VERSION ""

NS_ :

BS_:

BU_:

BO_ 3221225472 VECTOR__INDEPENDENT_SIG_MSG: 0 Vector__XXX
 SG_ NewSignal_0001 : 0|8@1+ (1,0) [0|0] "" Vector__XXX

BO_ 128 Sync: 0 Vector__XXX

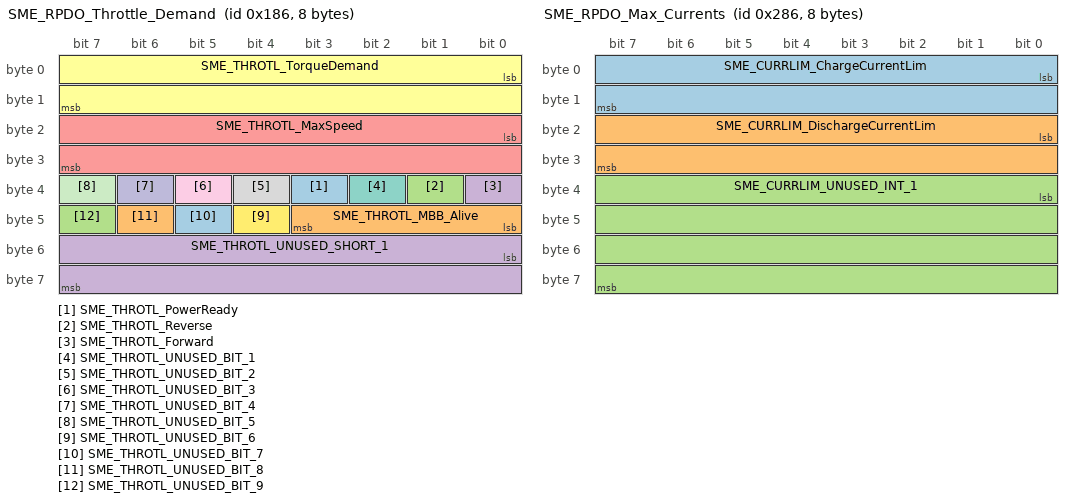
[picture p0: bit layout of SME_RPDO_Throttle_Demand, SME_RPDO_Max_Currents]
BO_ 390 SME_RPDO_Throttle_Demand: 8 Vector__XXX
 SG_ SME_THROTL_PowerReady : 35|1@1- (1,0) [0|1] "" Vector__XXX
 SG_ SME_THROTL_MBB_Alive : 40|4@1+ (1,0) [0|15] "" Vector__XXX
 SG_ SME_THROTL_Reverse : 33|1@1- (1,0) [0|1] "" Vector__XXX
 SG_ SME_THROTL_Forward : 32|1@1- (1,0) [0|1] "" Vector__XXX
 SG_ SME_THROTL_MaxSpeed : 16|16@1- (1,0) [-32768|32767] "RPM" Vector__XXX
 SG_ SME_THROTL_TorqueDemand : 0|16@1- (1,0) [-32767|32767] "Q15" Vector__XXX
 SG_ SME_THROTL_UNUSED_BIT_1 : 34|1@1+ (1,0) [0|0] "" Vector__XXX
 SG_ SME_THROTL_UNUSED_BIT_2 : 36|1@1+ (1,0) [0|0] "" Vector__XXX
 SG_ SME_THROTL_UNUSED_BIT_3 : 37|1@1+ (1,0) [0|0] "" Vector__XXX
 SG_ SME_THROTL_UNUSED_BIT_4 : 38|1@1+ (1,0) [0|0] "" Vector__XXX
 SG_ SME_THROTL_UNUSED_BIT_5 : 39|1@1+ (1,0) [0|0] "" Vector__XXX
 SG_ SME_THROTL_UNUSED_BIT_6 : 44|1@1+ (1,0) [0|0] "" Vector__XXX
 SG_ SME_THROTL_UNUSED_BIT_7 : 45|1@1+ (1,0) [0|0] "" Vector__XXX
 SG_ SME_THROTL_UNUSED_BIT_8 : 46|1@1+ (1,0) [0|0] "" Vector__XXX
 SG_ SME_THROTL_UNUSED_BIT_9 : 47|1@1+ (1,0) [0|0] "" Vector__XXX
 SG_ SME_THROTL_UNUSED_SHORT_1 : 48|16@1+ (1,0) [0|0] "" Vector__XXX

BO_ 646 SME_RPDO_Max_Currents: 8 Vector__XXX
 SG_ SME_CURRLIM_ChargeCurrentLim : 0|16@1+ (1,0) [0|65535] "A" Vector__XXX
 SG_ SME_CURRLIM_DischargeCurrentLim : 16|16@1+ (1,0) [0|65535] "A" Vector__XXX
 SG_ SME_CURRLIM_UNUSED_INT_1 : 32|32@1+ (1,0) [0|0] "" Vector__XXX

BO_ 1154 SME_TPDO_Torque_speed: 8 Vector__XXX
 SG_ SME_TRQSPD_SOC_Low_Traction : 32|1@1+ (1,0) [0|1] "" Vector__XXX
 SG_ SME_TRQSPD_SOC_Low_Hydraulic : 33|1@1+ (1,0) [0|1] "" Vector__XXX
 SG_ SME_TRQSPD_Reverse : 34|1@1+ (1,0) [0|1] "" Vector__XXX
 SG_ SME_TRQSPD_Forward : 35|1@1+ (1,0) [0|1] "" Vector__XXX
 SG_ SME_TRQSPD_Park_Brake : 36|1@1+ (1,0) [0|1] "" Vector__XXX
 SG_ SME_TRQSPD_Pedal_Brake : 37|1@1+ (1,0) [0|1] "" Vector__XXX
 SG_ SME_TRQSPD_Controller_Overtermp : 38|1@1+ (1,0) [0|1] "" Vector__XXX
 SG_ SME_TRQSPD_Key_switch_overvolt : 39|1@1+ (1,0) [0|1] "" Vector__XXX
 SG_ SME_TRQSPD_Key_switch_undervolt : 40|1@1+ (1,0) [0|1] "" Vector__XXX
 SG_ SME_TRQSPD_Running : 41|1@1+ (1,0) [0|1] "" Vector__XXX
 SG_ SME_TRQSPD_Traction : 42|1@1+ (1,0) [0|1] "" Vector__XXX
 SG_ SME_TRQSPD_Hydraulic : 43|1@1+ (1,0) [0|1] "" Vector__XXX
 SG_ SME_TRQSPD_Powering_Enabled : 44|1@1+ (1,0) [0|1] "" Vector__XXX
 SG_ SME_TRQSPD_Powering_Ready : 45|1@1+ (1,0) [0|1] "" Vector__XXX
 SG_ SME_TRQSPD_contactor_closed : 47|1@1+ (1,0) [0|1] "" Vector__XXX
 SG_ SME_TRQSPD_Precharging : 46|1@1+ (1,0) [0|1] "" Vector__XXX
 SG_ SME_TRQSPD_Speed : 0|16@1+ (1,0) [-32768|32767] "RPM" Vector__XXX
 SG_ SME_TRQSPD_MotorFlags : 48|16@1+ (1,0) [0|65535] "" Vector__XXX
 SG_ SME_TRQSPD_Torque : 16|16@1- (1,0) [-32767|32767] "Q15" Vector__XXX

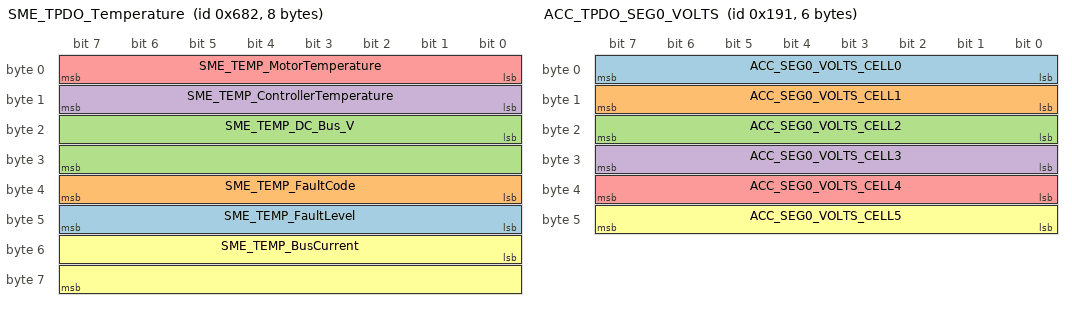
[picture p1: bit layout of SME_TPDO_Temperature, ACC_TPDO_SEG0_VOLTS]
BO_ 1666 SME_TPDO_Temperature: 8 Vector__XXX
 SG_ SME_TEMP_FaultLevel : 40|8@1+ (1,0) [0|255] "" Vector__XXX
 SG_ SME_TEMP_FaultCode : 32|8@1+ (1,0) [0|255] "" Vector__XXX
 SG_ SME_TEMP_DC_Bus_V : 16|16@1+ (0.1,0) [0|6553.5] "V" Vector__XXX
 SG_ SME_TEMP_ControllerTemperature : 8|8@1+ (1,-40) [0|255] "C" Vector__XXX
 SG_ SME_TEMP_MotorTemperature : 0|8@1+ (1,-40) [0|255] "C" Vector__XXX
 SG_ SME_TEMP_BusCurrent : 48|16@1- (0.1,0) [-3276.8|3276.7] "A" Vector__XXX

BO_ 400 ACC_TPDO_STATUS: 8 Vector__XXX

BO_ 656 ACC_TPDO_POWER: 8 Vector__XXX
 SG_ ACC_POWER_PACK_VOLTAGE : 0|16@1+ (0.01,0) [0|655.35] "V" Vector__XXX
 SG_ ACC_POWER_SOC : 16|8@1+ (1,0) [0|255] "Percentage" Vector__XXX

BO_ 401 ACC_TPDO_SEG0_VOLTS: 6 Vector__XXX
 SG_ ACC_SEG0_VOLTS_CELL0 : 0|8@1+ (0.01,2) [2|4.55] "V" Vector__XXX
 SG_ ACC_SEG0_VOLTS_CELL1 : 8|8@1+ (0.01,2) [2|4.55] "V" Vector__XXX
 SG_ ACC_SEG0_VOLTS_CELL2 : 16|8@1+ (0.01,2) [2|4.55] "V" Vector__XXX
 SG_ ACC_SEG0_VOLTS_CELL3 : 24|8@1+ (0.01,2) [2|4.55] "V" Vector__XXX
 SG_ ACC_SEG0_VOLTS_CELL4 : 32|8@1+ (0.01,2) [2|4.55] "V" Vector__XXX
 SG_ ACC_SEG0_VOLTS_CELL5 : 40|8@1+ (0.01,2) [2|4.55] "V" Vector__XXX

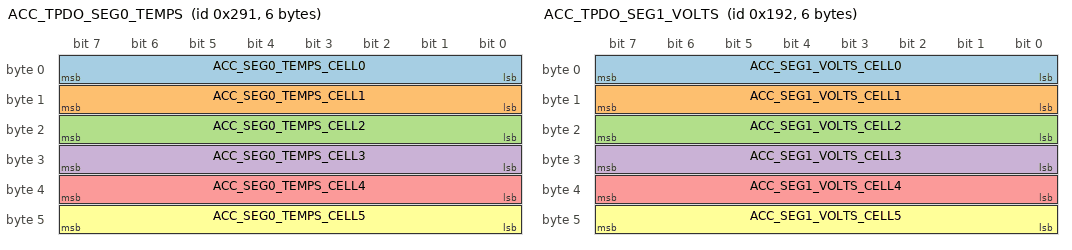
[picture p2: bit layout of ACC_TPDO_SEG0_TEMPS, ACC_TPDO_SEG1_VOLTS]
BO_ 657 ACC_TPDO_SEG0_TEMPS: 6 Vector__XXX
 SG_ ACC_SEG0_TEMPS_CELL0 : 0|8@1- (1,0) [-128|127] "C" Vector__XXX
 SG_ ACC_SEG0_TEMPS_CELL1 : 8|8@1- (1,0) [-128|127] "C" Vector__XXX
 SG_ ACC_SEG0_TEMPS_CELL2 : 16|8@1- (1,0) [-128|127] "C" Vector__XXX
 SG_ ACC_SEG0_TEMPS_CELL3 : 24|8@1- (1,0) [-128|127] "C" Vector__XXX
 SG_ ACC_SEG0_TEMPS_CELL4 : 32|8@1- (1,0) [-128|127] "C" Vector__XXX
 SG_ ACC_SEG0_TEMPS_CELL5 : 40|8@1- (1,0) [-128|127] "C" Vector__XXX

BO_ 402 ACC_TPDO_SEG1_VOLTS: 6 Vector__XXX
 SG_ ACC_SEG1_VOLTS_CELL0 : 0|8@1+ (0.01,2) [2|4.55] "V" Vector__XXX
 SG_ ACC_SEG1_VOLTS_CELL1 : 8|8@1+ (0.01,2) [2|4.55] "V" Vector__XXX
 SG_ ACC_SEG1_VOLTS_CELL2 : 16|8@1+ (0.01,2) [2|4.55] "V" Vector__XXX
 SG_ ACC_SEG1_VOLTS_CELL3 : 24|8@1+ (0.01,2) [2|4.55] "V" Vector__XXX
 SG_ ACC_SEG1_VOLTS_CELL4 : 32|8@1+ (0.01,2) [2|4.55] "V" Vector__XXX
 SG_ ACC_SEG1_VOLTS_CELL5 : 40|8@1+ (0.01,2) [2|4.55] "V" Vector__XXX

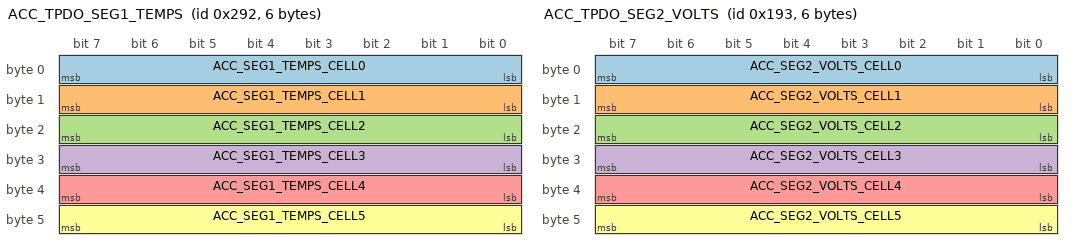
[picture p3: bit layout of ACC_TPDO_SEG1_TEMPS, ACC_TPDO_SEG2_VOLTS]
BO_ 658 ACC_TPDO_SEG1_TEMPS: 6 Vector__XXX
 SG_ ACC_SEG1_TEMPS_CELL0 : 0|8@1- (1,0) [-128|127] "C" Vector__XXX
 SG_ ACC_SEG1_TEMPS_CELL1 : 8|8@1- (1,0) [-128|127] "C" Vector__XXX
 SG_ ACC_SEG1_TEMPS_CELL2 : 16|8@1- (1,0) [-128|127] "C" Vector__XXX
 SG_ ACC_SEG1_TEMPS_CELL3 : 24|8@1- (1,0) [-128|127] "C" Vector__XXX
 SG_ ACC_SEG1_TEMPS_CELL4 : 32|8@1- (1,0) [-128|127] "C" Vector__XXX
 SG_ ACC_SEG1_TEMPS_CELL5 : 40|8@1- (1,0) [-128|127] "C" Vector__XXX

BO_ 403 ACC_TPDO_SEG2_VOLTS: 6 Vector__XXX
 SG_ ACC_SEG2_VOLTS_CELL0 : 0|8@1+ (0.01,2) [2|4.55] "V" Vector__XXX
 SG_ ACC_SEG2_VOLTS_CELL1 : 8|8@1+ (0.01,2) [2|4.55] "V" Vector__XXX
 SG_ ACC_SEG2_VOLTS_CELL2 : 16|8@1+ (0.01,2) [2|4.55] "V" Vector__XXX
 SG_ ACC_SEG2_VOLTS_CELL3 : 24|8@1+ (0.01,2) [2|4.55] "V" Vector__XXX
 SG_ ACC_SEG2_VOLTS_CELL4 : 32|8@1+ (0.01,2) [2|4.55] "V" Vector__XXX
 SG_ ACC_SEG2_VOLTS_CELL5 : 40|8@1+ (0.01,2) [2|4.55] "V" Vector__XXX

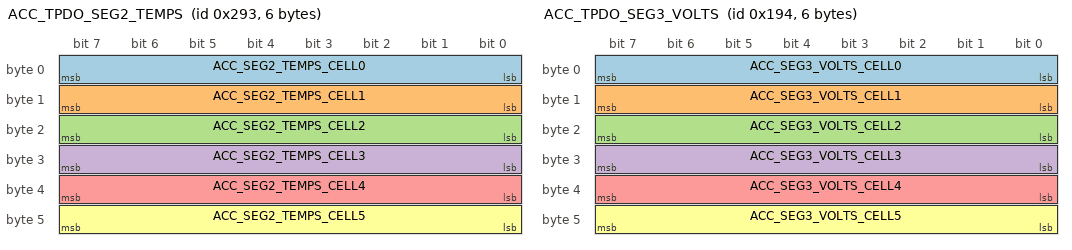
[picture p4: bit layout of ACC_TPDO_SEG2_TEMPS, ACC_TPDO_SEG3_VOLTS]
BO_ 659 ACC_TPDO_SEG2_TEMPS: 6 Vector__XXX
 SG_ ACC_SEG2_TEMPS_CELL0 : 0|8@1- (1,0) [-128|127] "C" Vector__XXX
 SG_ ACC_SEG2_TEMPS_CELL1 : 8|8@1- (1,0) [-128|127] "C" Vector__XXX
 SG_ ACC_SEG2_TEMPS_CELL2 : 16|8@1- (1,0) [-128|127] "C" Vector__XXX
 SG_ ACC_SEG2_TEMPS_CELL3 : 24|8@1- (1,0) [-128|127] "C" Vector__XXX
 SG_ ACC_SEG2_TEMPS_CELL4 : 32|8@1- (1,0) [-128|127] "C" Vector__XXX
 SG_ ACC_SEG2_TEMPS_CELL5 : 40|8@1- (1,0) [-128|127] "C" Vector__XXX

BO_ 404 ACC_TPDO_SEG3_VOLTS: 6 Vector__XXX
 SG_ ACC_SEG3_VOLTS_CELL0 : 0|8@1+ (0.01,2) [2|4.55] "V" Vector__XXX
 SG_ ACC_SEG3_VOLTS_CELL1 : 8|8@1+ (0.01,2) [2|4.55] "V" Vector__XXX
 SG_ ACC_SEG3_VOLTS_CELL2 : 16|8@1+ (0.01,2) [2|4.55] "V" Vector__XXX
 SG_ ACC_SEG3_VOLTS_CELL3 : 24|8@1+ (0.01,2) [2|4.55] "V" Vector__XXX
 SG_ ACC_SEG3_VOLTS_CELL4 : 32|8@1+ (0.01,2) [2|4.55] "V" Vector__XXX
 SG_ ACC_SEG3_VOLTS_CELL5 : 40|8@1+ (0.01,2) [2|4.55] "V" Vector__XXX

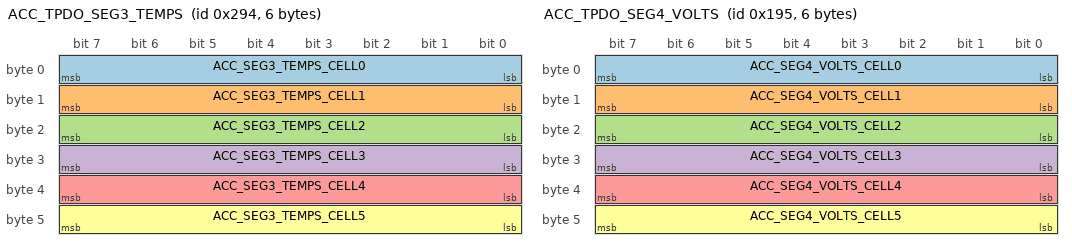
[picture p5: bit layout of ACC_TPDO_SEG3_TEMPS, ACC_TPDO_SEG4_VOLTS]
BO_ 660 ACC_TPDO_SEG3_TEMPS: 6 Vector__XXX
 SG_ ACC_SEG3_TEMPS_CELL0 : 0|8@1- (1,0) [-128|127] "C" Vector__XXX
 SG_ ACC_SEG3_TEMPS_CELL1 : 8|8@1- (1,0) [-128|127] "C" Vector__XXX
 SG_ ACC_SEG3_TEMPS_CELL2 : 16|8@1- (1,0) [-128|127] "C" Vector__XXX
 SG_ ACC_SEG3_TEMPS_CELL3 : 24|8@1- (1,0) [-128|127] "C" Vector__XXX
 SG_ ACC_SEG3_TEMPS_CELL4 : 32|8@1- (1,0) [-128|127] "C" Vector__XXX
 SG_ ACC_SEG3_TEMPS_CELL5 : 40|8@1- (1,0) [-128|127] "C" Vector__XXX

BO_ 405 ACC_TPDO_SEG4_VOLTS: 6 Vector__XXX
 SG_ ACC_SEG4_VOLTS_CELL0 : 0|8@1+ (0.01,2) [2|4.55] "V" Vector__XXX
 SG_ ACC_SEG4_VOLTS_CELL1 : 8|8@1+ (0.01,2) [2|4.55] "V" Vector__XXX
 SG_ ACC_SEG4_VOLTS_CELL2 : 16|8@1+ (0.01,2) [2|4.55] "V" Vector__XXX
 SG_ ACC_SEG4_VOLTS_CELL3 : 24|8@1+ (0.01,2) [2|4.55] "V" Vector__XXX
 SG_ ACC_SEG4_VOLTS_CELL4 : 32|8@1+ (0.01,2) [2|4.55] "V" Vector__XXX
 SG_ ACC_SEG4_VOLTS_CELL5 : 40|8@1+ (0.01,2) [2|4.55] "V" Vector__XXX

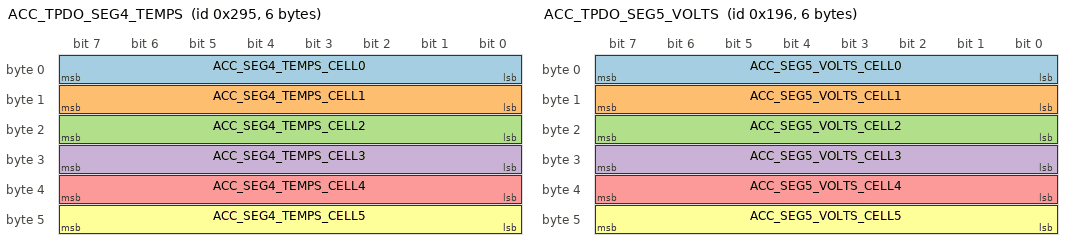
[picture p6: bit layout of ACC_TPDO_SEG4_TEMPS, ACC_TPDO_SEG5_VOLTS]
BO_ 661 ACC_TPDO_SEG4_TEMPS: 6 Vector__XXX
 SG_ ACC_SEG4_TEMPS_CELL0 : 0|8@1- (1,0) [-128|127] "C" Vector__XXX
 SG_ ACC_SEG4_TEMPS_CELL1 : 8|8@1- (1,0) [-128|127] "C" Vector__XXX
 SG_ ACC_SEG4_TEMPS_CELL2 : 16|8@1- (1,0) [-128|127] "C" Vector__XXX
 SG_ ACC_SEG4_TEMPS_CELL3 : 24|8@1- (1,0) [-128|127] "C" Vector__XXX
 SG_ ACC_SEG4_TEMPS_CELL4 : 32|8@1- (1,0) [-128|127] "C" Vector__XXX
 SG_ ACC_SEG4_TEMPS_CELL5 : 40|8@1- (1,0) [-128|127] "C" Vector__XXX

BO_ 406 ACC_TPDO_SEG5_VOLTS: 6 Vector__XXX
 SG_ ACC_SEG5_VOLTS_CELL0 : 0|8@1+ (0.01,2) [2|4.55] "V" Vector__XXX
 SG_ ACC_SEG5_VOLTS_CELL1 : 8|8@1+ (0.01,2) [2|4.55] "V" Vector__XXX
 SG_ ACC_SEG5_VOLTS_CELL2 : 16|8@1+ (0.01,2) [2|4.55] "V" Vector__XXX
 SG_ ACC_SEG5_VOLTS_CELL3 : 24|8@1+ (0.01,2) [2|4.55] "V" Vector__XXX
 SG_ ACC_SEG5_VOLTS_CELL4 : 32|8@1+ (0.01,2) [2|4.55] "V" Vector__XXX
 SG_ ACC_SEG5_VOLTS_CELL5 : 40|8@1+ (0.01,2) [2|4.55] "V" Vector__XXX

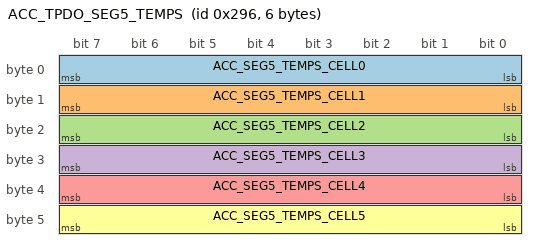
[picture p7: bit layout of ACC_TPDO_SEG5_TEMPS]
BO_ 662 ACC_TPDO_SEG5_TEMPS: 6 Vector__XXX
 SG_ ACC_SEG5_TEMPS_CELL0 : 0|8@1- (1,0) [-128|127] "C" Vector__XXX
 SG_ ACC_SEG5_TEMPS_CELL1 : 8|8@1- (1,0) [-128|127] "C" Vector__XXX
 SG_ ACC_SEG5_TEMPS_CELL2 : 16|8@1- (1,0) [-128|127] "C" Vector__XXX
 SG_ ACC_SEG5_TEMPS_CELL3 : 24|8@1- (1,0) [-128|127] "C" Vector__XXX
 SG_ ACC_SEG5_TEMPS_CELL4 : 32|8@1- (1,0) [-128|127] "C" Vector__XXX
 SG_ ACC_SEG5_TEMPS_CELL5 : 40|8@1- (1,0) [-128|127] "C" Vector__XXX

BA_DEF_  "BusType" STRING ;
BA_DEF_DEF_  "BusType" "CAN";
